# AT90PWM2B device description
Architecture: AVR8; Family: megaAVR
Registers are 8-bit, access not given, no defined reset value unless marked. A register's access mark holds for its fields unless they carry their own. Offsets are from the block's base; [hi:lo] are bit positions.

## EEPROM
Instances: EEPROM 0x00
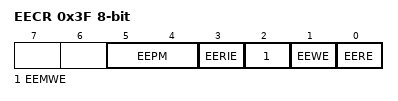
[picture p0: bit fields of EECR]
0x3F EECR — EEPROM Control Register
  [5:4] EEPM — EEPROM Programming Mode
  [3] EERIE — EEPROM Ready Interrupt Enable
  [2] EEMWE — EEPROM Master Write Enable
  [1] EEWE — EEPROM Write Enable
  [0] EERE — EEPROM Read Enable
0x40 EEDR — EEPROM Data Register
  [7:0] EEDR — EEPROM Data Bits
0x41 EEAR 16-bit — EEPROM Read/Write Access Bytes
  [11:0] EEAR — EEPROM Address bytes

## PSC0 — Power Stage Controller
Instances: PSC0 0x00
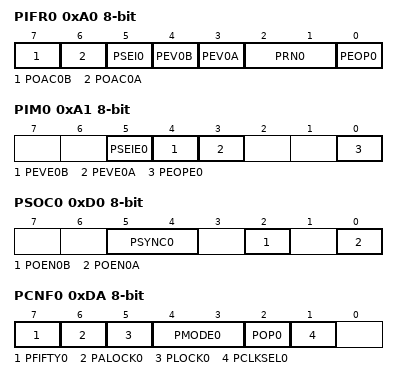
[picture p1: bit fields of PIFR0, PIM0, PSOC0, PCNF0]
0xA0 PIFR0 — PSC0 Interrupt Flag Register
  [7] POAC0B — PSC 0 Output A Activity
  [6] POAC0A — PSC 0 Output A Activity
  [5] PSEI0 — PSC 0 Synchro Error Interrupt
  [4] PEV0B — External Event B Interrupt
  [3] PEV0A — External Event A Interrupt
  [2:1] PRN0 — Ramp Number
  [0] PEOP0 — End of PSC0 Interrupt
0xA1 PIM0 — PSC0 Interrupt Mask Register
  [5] PSEIE0 — PSC 0 Synchro Error Interrupt Enable
  [4] PEVE0B — External Event B Interrupt Enable
  [3] PEVE0A — External Event A Interrupt Enable
  [0] PEOPE0 — End of Cycle Interrupt Enable
0xD0 PSOC0 — PSC0 Synchro and Output Configuration
  [5:4] PSYNC0 — Synchronization Out for ADC Selection
  [2] POEN0B — PSCOUT01 Output Enable
  [0] POEN0A — PSCOUT00 Output Enable
0xD2 OCR0SA 16-bit — Output Compare 0 SA Register
  [11:0] OCR0SA — Output Compare SA
0xD4 OCR0RA 16-bit — Output Compare 0 RA Register
  [11:0] OCR0RA — Output Compare RA
0xD6 OCR0SB 16-bit — Output Compare 0 SB Register
  [11:0] OCR0SB — Output Compare SB
0xD8 OCR0RB 16-bit — Output Compare 0 RB Register
  [15:0] OCR0RB — Output Compare RB
0xDA PCNF0 — PSC 0 Configuration Register
  [7] PFIFTY0 — PSC 0 Fifty
  [6] PALOCK0 — PSC 0 Autolock
  [5] PLOCK0 — PSC 0 Lock
  [4:3] PMODE0 — PSC 0 Mode
  [2] POP0 — PSC 0 Output Polarity
  [1] PCLKSEL0 — PSC 0 Input Clock Select
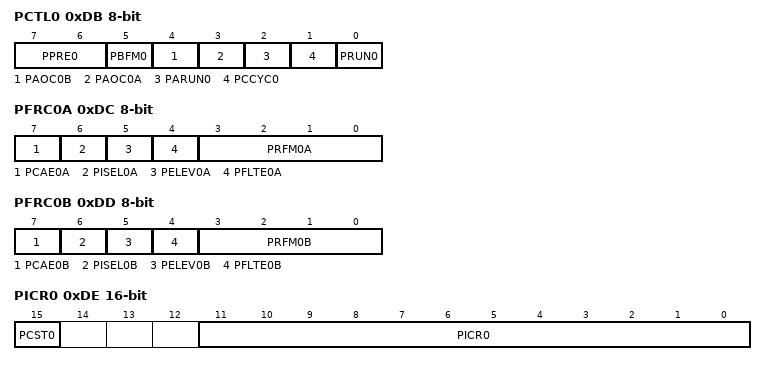
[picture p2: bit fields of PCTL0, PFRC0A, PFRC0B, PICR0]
0xDB PCTL0 — PSC 0 Control Register
  [7:6] PPRE0 — PSC 0 Prescaler Selects
  [5] PBFM0 — PSC 0 Balance Flank Width Modulation
  [4] PAOC0B — PSC 0 Asynchronous Output Control B
  [3] PAOC0A — PSC 0 Asynchronous Output Control A
  [2] PARUN0 — PSC0 Auto Run
  [1] PCCYC0 — PSC0 Complete Cycle
  [0] PRUN0 — PSC 0 Run
0xDC PFRC0A — PSC 0 Input A Control
  [7] PCAE0A — PSC 0 Capture Enable Input Part A
  [6] PISEL0A — PSC 0 Input Select for Part A
  [5] PELEV0A — PSC 0 Edge Level Selector on Input Part A
  [4] PFLTE0A — PSC 0 Filter Enable on Input Part A
  [3:0] PRFM0A — PSC 0 Retrigger and Fault Mode for Part A
0xDD PFRC0B — PSC 0 Input B Control
  [7] PCAE0B — PSC 0 Capture Enable Input Part B
  [6] PISEL0B — PSC 0 Input Select for Part B
  [5] PELEV0B — PSC 0 Edge Level Selector on Input Part B
  [4] PFLTE0B — PSC 0 Filter Enable on Input Part B
  [3:0] PRFM0B — PSC 0 Retrigger and Fault Mode for Part B
0xDE PICR0 16-bit — PSC 0 Input Capture Register
  [15] PCST0 — PSC 0 Input Capture Software Trig
  [11:0] PICR0 — PSC 0 Input Capture Bytes

## PSC2 — Power Stage Controller
Instances: PSC2 0x00
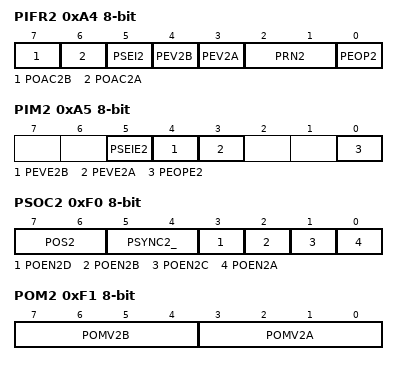
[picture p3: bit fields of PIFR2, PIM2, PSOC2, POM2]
0xA4 PIFR2 — PSC2 Interrupt Flag Register
  [7] POAC2B — PSC 2 Output A Activity
  [6] POAC2A — PSC 2 Output A Activity
  [5] PSEI2 — PSC 2 Synchro Error Interrupt
  [4] PEV2B — External Event B Interrupt
  [3] PEV2A — External Event A Interrupt
  [2:1] PRN2 — Ramp Number
  [0] PEOP2 — End of PSC2 Interrupt
0xA5 PIM2 — PSC2 Interrupt Mask Register
  [5] PSEIE2 — PSC 2 Synchro Error Interrupt Enable
  [4] PEVE2B — External Event B Interrupt Enable
  [3] PEVE2A — External Event A Interrupt Enable
  [0] PEOPE2 — End of Cycle Interrupt Enable
0xF0 PSOC2 — PSC2 Synchro and Output Configuration
  [7:6] POS2 (bit 2 of the value upward) — PSC 2 Output 23 Select
  [5:4] PSYNC2_ — Synchronization Out for ADC Selection
  [3] POEN2D — PSCOUT23 Output Enable
  [2] POEN2B — PSCOUT21 Output Enable
  [1] POEN2C — PSCOUT22 Output Enable
  [0] POEN2A — PSCOUT20 Output Enable
0xF1 POM2 — PSC 2 Output Matrix
  [7:4] POMV2B — Output Matrix Output B Ramps
  [3:0] POMV2A — Output Matrix Output A Ramps
0xF2 OCR2SA 16-bit — Output Compare 2 SA Register
  [11:0] OCR2SA — Output Compare SA
0xF4 OCR2RA 16-bit — Output Compare 2 RA Register
  [11:0] OCR2RA — Output Compare RA
0xF6 OCR2SB 16-bit — Output Compare 2 SB Register
  [11:0] OCR2SB — Output Compare SB
0xF8 OCR2RB 16-bit — Output Compare 2 RB Register
  [15:0] OCR2RB — Output Compare RB
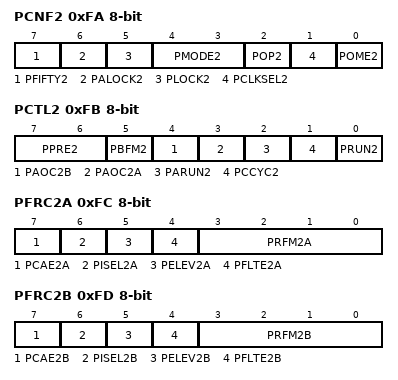
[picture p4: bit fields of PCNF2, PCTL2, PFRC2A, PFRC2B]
0xFA PCNF2 — PSC 2 Configuration Register
  [7] PFIFTY2 — PSC 2 Fifty
  [6] PALOCK2 — PSC 2 Autolock
  [5] PLOCK2 — PSC 2 Lock
  [4:3] PMODE2 — PSC 2 Mode
  [2] POP2 — PSC 2 Output Polarity
  [1] PCLKSEL2 — PSC 2 Input Clock Select
  [0] POME2 — PSC 2 Output Matrix Enable
0xFB PCTL2 — PSC 2 Control Register
  [7:6] PPRE2 — PSC 2 Prescaler Selects
  [5] PBFM2 — Balance Flank Width Modulation
  [4] PAOC2B — PSC 2 Asynchronous Output Control B
  [3] PAOC2A — PSC 2 Asynchronous Output Control A
  [2] PARUN2 — PSC2 Auto Run
  [1] PCCYC2 — PSC2 Complete Cycle
  [0] PRUN2 — PSC 2 Run
0xFC PFRC2A — PSC 2 Input B Control
  [7] PCAE2A — PSC 2 Capture Enable Input Part A
  [6] PISEL2A — PSC 2 Input Select for Part A
  [5] PELEV2A — PSC 2 Edge Level Selector on Input Part A
  [4] PFLTE2A — PSC 2 Filter Enable on Input Part A
  [3:0] PRFM2A — PSC 2 Retrigger and Fault Mode for Part A
0xFD PFRC2B — PSC 2 Input B Control
  [7] PCAE2B — PSC 2 Capture Enable Input Part B
  [6] PISEL2B — PSC 2 Input Select for Part B
  [5] PELEV2B — PSC 2 Edge Level Selector on Input Part B
  [4] PFLTE2B — PSC 2 Filter Enable on Input Part B
  [3:0] PRFM2B — PSC 2 Retrigger and Fault Mode for Part B
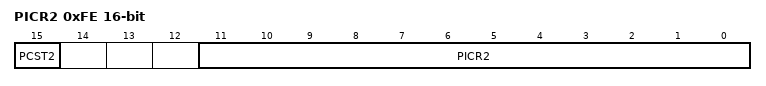
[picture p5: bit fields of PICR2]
0xFE PICR2 16-bit — PSC 2 Input Capture Register
  [15] PCST2 — PSC 2 Input Capture Software Trig
  [11:0] PICR2 — PSC 2 Input Capture Bytes
